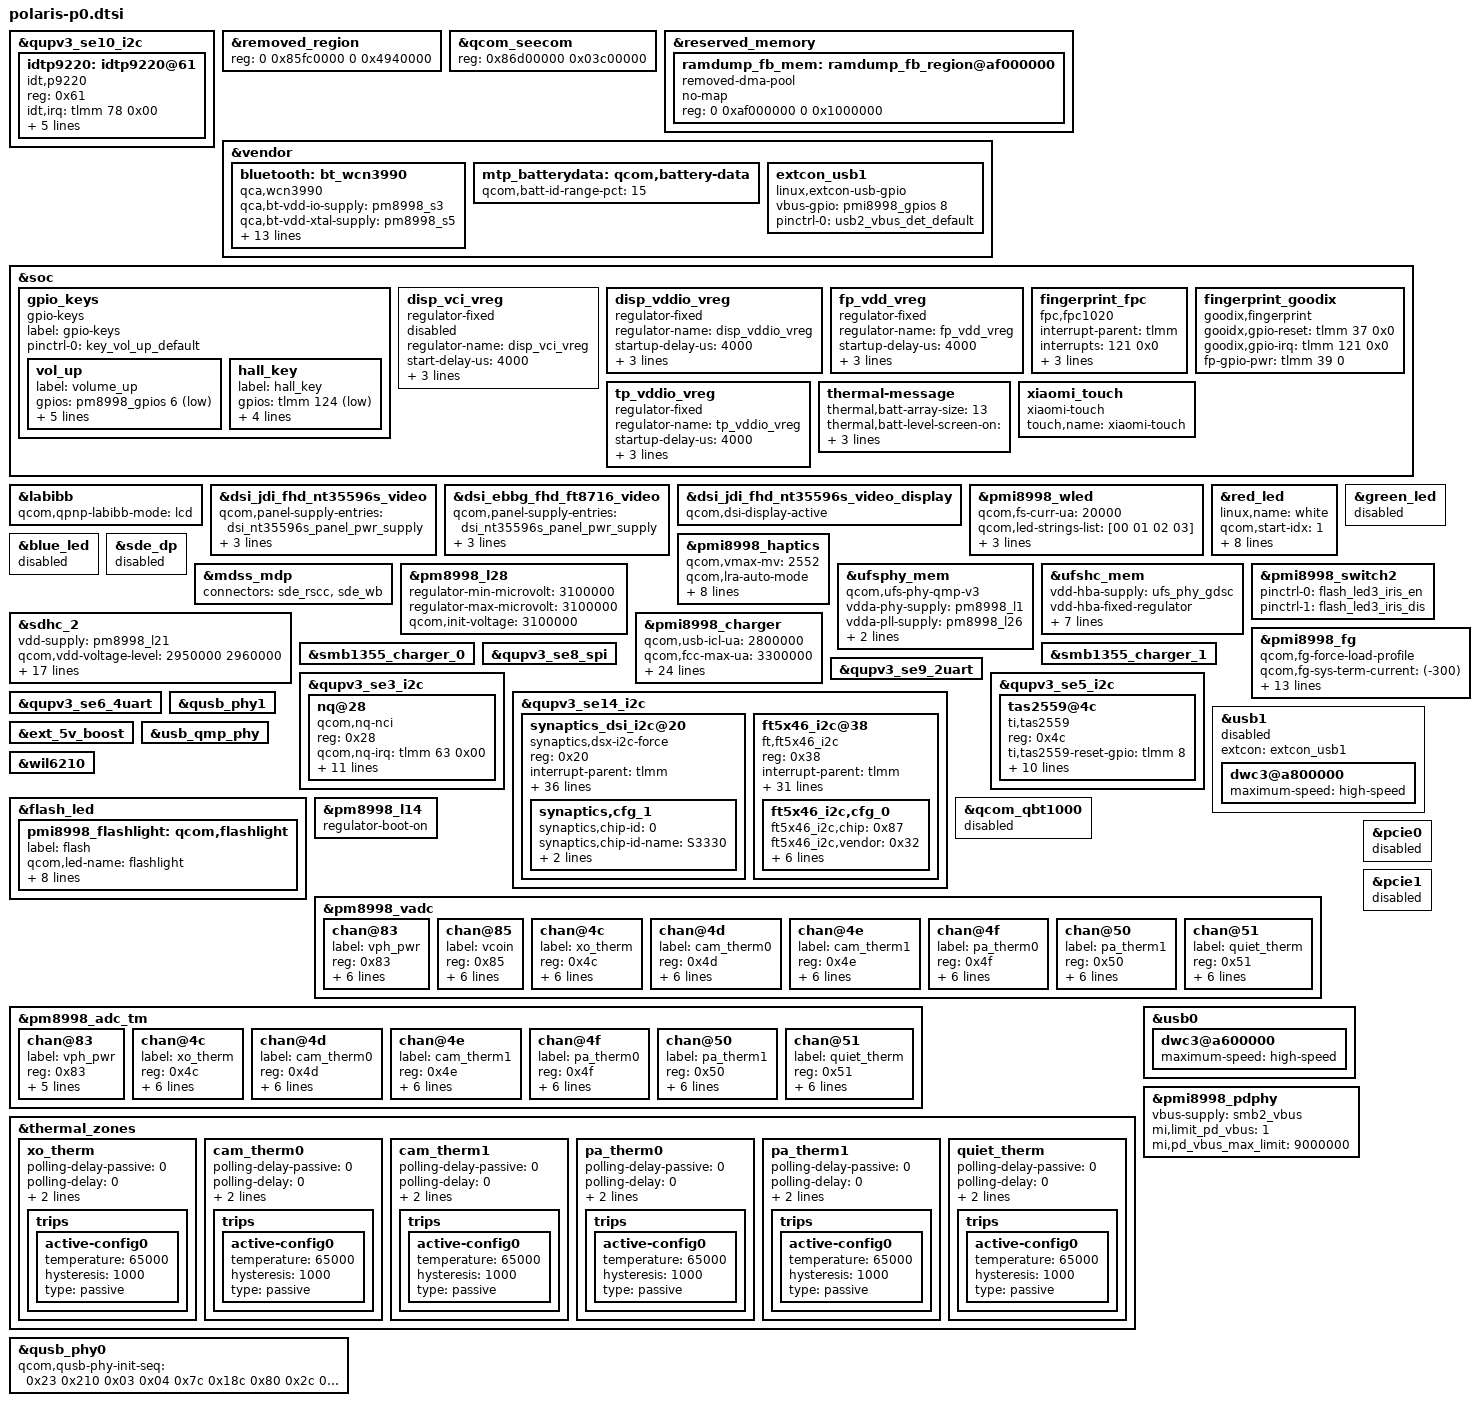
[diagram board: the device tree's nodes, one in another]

/* Copyright (c) 2016-2017, The Linux Foundation. All rights reserved.
 * Copyright (C) 2019 XiaoMi, Inc.
 *
 * This program is free software; you can redistribute it and/or modify
 * it under the terms of the GNU General Public License version 2 and
 * only version 2 as published by the Free Software Foundation.
 *
 * This program is distributed in the hope that it will be useful,
 * but WITHOUT ANY WARRANTY; without even the implied warranty of
 * MERCHANTABILITY or FITNESS FOR A PARTICULAR PURPOSE.  See the
 * GNU General Public License for more details.
 */

#include <dt-bindings/gpio/gpio.h>
#include "sdm845-pmic-overlay.dtsi"
#include "sdm845-pinctrl-overlay.dtsi"
#include "polaris-camera-sensor-mtp.dtsi"
#include "xiaomi-sde-display.dtsi"

&qupv3_se10_i2c {
#include "smb1355.dtsi"
};

&removed_region {
	reg = <0 0x85fc0000 0 0x4940000>;
};

&qcom_seecom {
	reg = <0x86d00000 0x03c00000>;
};

&reserved_memory {
		ramdump_fb_mem: ramdump_fb_region@af000000 {
			compatible = "removed-dma-pool";
			no-map;
			reg = <0 0xaf000000 0 0x1000000>;
		};
};

&vendor {
	bluetooth: bt_wcn3990 {
		compatible = "qca,wcn3990";
		qca,bt-vdd-io-supply = <&pm8998_s3>;
		qca,bt-vdd-xtal-supply = <&pm8998_s5>;
		qca,bt-vdd-core-supply = <&pm8998_l7>;
		qca,bt-vdd-pa-supply = <&pm8998_l17>;
		qca,bt-vdd-ldo-supply = <&pm8998_l25>;

		qca,bt-vdd-io-voltage-level = <1352000 1352000>;
		qca,bt-vdd-xtal-voltage-level = <2040000 2040000>;
		qca,bt-vdd-core-voltage-level = <1800000 1800000>;
		qca,bt-vdd-pa-voltage-level = <1304000 1304000>;
		qca,bt-vdd-ldo-voltage-level = <3312000 3312000>;

		qca,bt-vdd-io-current-level = <1>; /* LPM/PFM */
		qca,bt-vdd-xtal-current-level = <1>; /* LPM/PFM */
		qca,bt-vdd-core-current-level = <1>; /* LPM/PFM */
		qca,bt-vdd-pa-current-level = <1>; /* LPM/PFM */
		qca,bt-vdd-ldo-current-level = <1>; /* LPM/PFM */
	};
};

&soc {
	gpio_keys {
		compatible = "gpio-keys";
		label = "gpio-keys";

		pinctrl-names = "default";
		pinctrl-0 = <&key_vol_up_default>;

		vol_up {
			label = "volume_up";
			gpios = <&pm8998_gpios 6 GPIO_ACTIVE_LOW>;
			linux,input-type = <1>;
			linux,code = <115>;
			gpio-key,wakeup;
			debounce-interval = <15>;
			linux,can-disable;
		};
		hall_key {
			label = "hall_key";
			gpios = <&tlmm 124 GPIO_ACTIVE_LOW>;
			linux,input-type = <5>;
			linux,code = <0>;
			gpio-key,wakeup;
			debounce-interval = <15>;
		};
	};
	disp_vci_vreg: disp_vci_vreg {
		compatible = "regulator-fixed";
		regulator-name = "disp_vci_vreg";
		start-delay-us = <4000>;
		enable-active-high;
		regulator-boot-on;
		gpio = <&tlmm 35 0>;
	};

	disp_vddio_vreg: disp_vddio_vreg {
		compatible = "regulator-fixed";
		regulator-name = "disp_vddio_vreg";
		startup-delay-us = <4000>;
		enable-active-high;
		regulator-boot-on;
		gpio = <&tlmm 90 0>;
	 };

	fp_vdd_vreg: fp_vdd_vreg {
		compatible = "regulator-fixed";
		regulator-name = "fp_vdd_vreg";
		startup-delay-us = <4000>;
		enable-active-high;
		gpio = <&tlmm 39 0>;
		regulator-always-on;
	};

	fingerprint_fpc {
		status = "ok";
		compatible = "fpc,fpc1020";
		interrupt-parent = <&tlmm>;
		interrupts = <121 0x0>;
		fpc,gpio_irq    = <&tlmm 121 0x0>;
		/* fpc,enable-on-boot; */
		/* fpc,enable-wakeup;  */

		pinctrl-names = "fpc1020_reset_reset",
			"fpc1020_reset_active";

		pinctrl-0 = <&msm_gpio_37>;
		pinctrl-1 = <&msm_gpio_37_output_high>;
	};

	fingerprint_goodix {
		compatible = "goodix,fingerprint";
		gooidx,gpio-reset = <&tlmm 37 0x0>;
		goodix,gpio-irq = <&tlmm 121 0x0>;
		fp-gpio-pwr = <&tlmm 39 0>;
		status = "ok";
	};

    tp_vddio_vreg: tp_vddio_vreg {
	 compatible = "regulator-fixed";
	 regulator-name = "tp_vddio_vreg";
	 startup-delay-us = <4000>;
	 enable-active-high;
	 regulator-boot-on;
	 gpio = <&tlmm 23 0>;
     };

	thermal-message {
		thermal,batt-array-size = "13";
		thermal,batt-level-screen-on = "0 2 4 6 8 9 10 11 12 13 14 14 16";
		thermal,batt-level-screen-off = "0 1 1 1 3 4 5 5 5 7 9 14 16";
	};

	xiaomi_touch {
		compatible = "xiaomi-touch";
		status = "ok";
		touch,name = "xiaomi-touch";
	};

};

&labibb {
	status = "ok";
	qcom,qpnp-labibb-mode = "lcd";
};

&dsi_jdi_fhd_nt35596s_video {
	qcom,panel-supply-entries = <&dsi_nt35596s_panel_pwr_supply>;
	qcom,mdss-dsi-bl-pmic-control-type = "bl_ctrl_wled";
	qcom,platform-reset-gpio = <&tlmm 6 0>;
};

&dsi_ebbg_fhd_ft8716_video {
	qcom,panel-supply-entries = <&dsi_nt35596s_panel_pwr_supply>;
	qcom,mdss-dsi-bl-pmic-control-type = "bl_ctrl_wled";
	qcom,platform-reset-gpio = <&tlmm 6 0>;
};

&dsi_jdi_fhd_nt35596s_video_display {
	qcom,dsi-display-active;
};

&pmi8998_wled {
	status = "okay";
	qcom,fs-curr-ua = <20000>;
	qcom,led-strings-list = [00 01 02 03];
	qcom,ovp-mv = <19600>;
	qcom,en-cabc;
	qcom,switch-freq-khz = <600>;
};

&red_led {
	linux,name = "white";
	qcom,start-idx = <1>;
	qcom,idx-len = <18>;
	qcom,duty-pcts = [00 01 02 03 04 05 06 07 08
			08 07 06 05 04 03 02 01 00];
	qcom,lut-flags = <3>;
	qcom,pause-lo = <0>;
	qcom,pause-hi = <0>;
	qcom,ramp-step-ms = <142>;
	qcom,use-blink;
	status = "okay";
};

&green_led {
	status = "disabled";
};

&blue_led {
	status = "disabled";
};

&sde_dp {
	status = "disabled";
};

&disp_vci_vreg {
	status = "disabled";
};

&pmi8998_haptics {
	qcom,vmax-mv = <2552>;
	qcom,lra-auto-mode;
	qcom,wave-play-rate-us = <4878>;
	qcom,wave-shape = "sine";
	qcom,lra-high-z = "opt1";
	qcom,lra-auto-res-mode = "qwd";
	qcom,lra-res-cal-period = <4>;
	qcom,effect-max = <3>;
	qcom,effect-arry = [3e 3e be a0 00 00 00 00
	3e 3e 3e be be 00 00 00
	3e 3e 3e 3e be be a0 90];
	status = "okay";
};

&mdss_mdp {
	#cooling-cells = <2>;
	connectors = <&sde_rscc &sde_wb>;
};

&pm8998_l28{
	regulator-min-microvolt = <3100000>;
	regulator-max-microvolt = <3100000>;
	qcom,init-voltage = <3100000>;
};

&ufsphy_mem {
	compatible = "qcom,ufs-phy-qmp-v3";

	vdda-phy-supply = <&pm8998_l1>; /* 0.88v */
	vdda-pll-supply = <&pm8998_l26>; /* 1.2v */
	vdda-phy-max-microamp = <62900>;
	vdda-pll-max-microamp = <18300>;

	status = "ok";
};

&ufshc_mem {
	vdd-hba-supply = <&ufs_phy_gdsc>;
	vdd-hba-fixed-regulator;
	vcc-supply = <&pm8998_l20>;
	vcc-voltage-level = <2950000 2960000>;
	vccq2-supply = <&pm8998_s4>;
	vcc-max-microamp = <600000>;
	vccq2-max-microamp = <600000>;

	qcom,vddp-ref-clk-supply = <&pm8998_l2>;
	qcom,vddp-ref-clk-max-microamp = <100>;

	status = "ok";
};

&sdhc_2 {
	vdd-supply = <&pm8998_l21>;
	qcom,vdd-voltage-level = <2950000 2960000>;
	qcom,vdd-current-level = <200 800000>;

	vdd-io-supply = <&pm8998_l13>;
	qcom,vdd-io-voltage-level = <1808000 2960000>;
	qcom,vdd-io-current-level = <200 22000>;

	pinctrl-names = "active", "sleep", "ds_400KHz",
			"ds_50MHz", "ds_100MHz", "ds_200MHz";
	pinctrl-0 = <&sdc2_clk_on  &sdc2_cmd_on &sdc2_data_on &storage_cd>;
	pinctrl-1 = <&sdc2_clk_off &sdc2_cmd_off &sdc2_data_off &storage_cd>;
	pinctrl-2 = <&sdc2_clk_ds_400KHz
			&sdc2_cmd_ds_400KHz &sdc2_data_ds_400KHz>;
	pinctrl-3 = <&sdc2_clk_ds_50MHz
			&sdc2_cmd_ds_50MHz &sdc2_data_ds_50MHz>;
	pinctrl-4 = <&sdc2_clk_ds_100MHz
			&sdc2_cmd_ds_100MHz &sdc2_data_ds_100MHz>;
	pinctrl-5 = <&sdc2_clk_ds_200MHz
			&sdc2_cmd_ds_200MHz &sdc2_data_ds_200MHz>;

	cd-gpios = <&tlmm 126 GPIO_ACTIVE_LOW>;

	status = "ok";
};

&pmi8998_switch2 {
	pinctrl-names = "led_enable", "led_disable";
	pinctrl-0 = <&flash_led3_iris_en>;
	pinctrl-1 = <&flash_led3_iris_dis>;
};

&vendor{
	mtp_batterydata: qcom,battery-data {
		qcom,batt-id-range-pct = <15>;
		#include "batterydata-d5-atl-3400mAh.dtsi"
		#include "batterydata-d5-cos-3400mAh.dtsi"
		#include "batterydata-itech-3020mAh.dtsi"
	};

	extcon_usb1: extcon_usb1 {
		compatible = "linux,extcon-usb-gpio";
		vbus-gpio = <&pmi8998_gpios 8 GPIO_ACTIVE_HIGH>;

		pinctrl-names = "default";
		pinctrl-0 = <&usb2_vbus_det_default>;
	};
};
&pmi8998_charger {
	qcom,usb-icl-ua = <2800000>;
	qcom,fcc-max-ua = <3300000>;
	qcom,dc-icl-ua = <950000>;
	qcom,fcc-low-temp-delta = <2970000>;
	qcom,fcc-hot-temp-delta = <1650000>;
	qcom,fcc-cool-temp-delta = <2310000>;
	qcom,auto-recharge-soc;
	 qcom,sw-jeita-enable;
	qcom,dynamic-fv-enable;
	qcom,wireless-flag;
	qcom,wireless-support;
	qcom,thermal-mitigation
				= <1800000 1600000 1400000 1200000 1000000 1000000 1000000>;
	qcom,thermal-mitigation-dc
				= <800000 550000 450000 325000>;
	qcom,thermal-mitigation-dcp
				= <1800000 1800000 1800000 1800000 1800000 1800000 1800000
				   1800000 1800000 1800000 1800000 1800000 1600000 1400000
				   1200000 1000000>;
	qcom,thermal-mitigation-qc3
				= <2800000 2725000 2575000 2425000 2275000 2125000 2000000
				   1800000 1650000 1500000 1360000 1200000 1060000 900000
				   752500 525000>;
	qcom,thermal-mitigation-qc2
				= <1625000 1625000 1625000 1625000 1625000 1525000 1425000
				   1325000 1225000 1125000 10255000 925000 825000 725000
				   625000 525000>;
	qcom,thermal-mitigation-pd-base
				= <3000000 2800000 2600000 2400000 2200000 2000000 1800000
				   1600000 1600000 1400000 1200000 1100000 1000000 900000
				   752500 525000>;

	io-channels = <&pmi8998_rradc 8>,
		<&pmi8998_rradc 10>,
		<&pmi8998_rradc 3>,
		<&pmi8998_rradc 4>,
		<&pmi8998_rradc 5>;
	io-channel-names = "charger_temp",
		"charger_temp_max",
		"usbin_i",
		"usbin_v",
		"dcin_i";
};

&pmi8998_fg {
	qcom,fg-force-load-profile;
	qcom,fg-sys-term-current = <(-300)>;
	qcom,fg-chg-term-current = <200>;
	qcom,fg-auto-recharge-soc;
	qcom,fg-recharge-soc-thr = <99>;
	qcom,fg-cutoff-voltage = <3400>;
	qcom,fg-cutoff-current = <200>;
	qcom,fg-empty-voltage = <3100>;
	qcom,fg-jeita-hyst-temp = <2>;
	qcom,fg-jeita-thresholds = <0 15 45 60>;
	qcom,fg-esr-clamp-mohms = <60>;
	qcom,fg-batt-temp-delta = <6>;
	qcom,battery-data = <&mtp_batterydata>;
	qcom,slope-limit-temp-threshold = <100>;
	qcom,slope-limit-coeffs = <10 11 12 13>;
};

&smb1355_charger_0 {
	status = "ok";
};

&smb1355_charger_1 {
	status = "ok";
};

&qupv3_se9_2uart {
	status = "ok";
};

&qupv3_se8_spi {
	status = "ok";
};

&qupv3_se3_i2c {
	status = "ok";
	nq@28 {
		compatible = "qcom,nq-nci";
		reg = <0x28>;
		qcom,nq-irq = <&tlmm 63 0x00>;
		qcom,nq-ven = <&tlmm 12 0x00>;
		qcom,nq-firm = <&tlmm 88 0x00>;
		qcom,nq-clkreq = <&pm8998_gpios 21 0x00>;
		qcom,nq-esepwr = <&tlmm 116 0x00>;
		interrupt-parent = <&tlmm>;
		qcom,clk-src = "BBCLK3";
		interrupts = <63 0>;
		interrupt-names = "nfc_irq";
		pinctrl-names = "nfc_active", "nfc_suspend";
		 pinctrl-0 = <&nfc_int_active
		              &nfc_enable_active
		              &nfc_clk_default>;
		pinctrl-1 = <&nfc_int_suspend &nfc_enable_suspend>;
		clocks = <&clock_rpmh RPMH_LN_BB_CLK3>;
		clock-names = "ref_clk";
	};
};

&qupv3_se5_i2c {
	status = "ok";
	/*smart PA*/
	tas2559@4c{
		compatible = "ti,tas2559";
		reg = <0x4c>;
		ti,tas2559-reset-gpio = <&tlmm 8 0>;
		ti,tas2560-reset-gpio = <&tlmm 25 0>;
		ti,tas2559-irq-gpio = <&tlmm 24 0>;
		ti,tas2560-irq-gpio = <&tlmm 30 0>;
		ti,tas2559-addr = <0x4c>;
		ti,tas2560-addr = <0x4d>;
		ti,tas2559-channel = <0>; /* 0, left; 1, right */
		ti,tas2560-channel = <1>; /* 0, left; 1, right */
		ti,ycrc-enable = <1>;           /* 0, disable; non-zero, enable */
		ti,echo-ref = <0>;              /* 0, left channel; 1, right channel; 2, both */
		ti,bit-rate = <16>;             /* 16, 20, 24, 32 */
		status = "ok";
	};

};

&qupv3_se10_i2c {
	status = "ok";
	idtp9220: idtp9220@61 {
		compatible = "idt,p9220";
		reg = <0x61>;
		idt,irq = <&tlmm 78 0x00>;
		idt,enable = <&tlmm 36 0x00>;
		interrupt-parent = <&tlmm>;
		interrupts = <78 0>;
		interrupt-names = "idt_irq";
		pinctrl-names = "idt_active", "idt_suspend";
		pinctrl-0 = <&idt_int_active &idt_enable_active>;
		pinctrl-1 = <&idt_int_suspend &idt_enable_suspend>;
	};
};

&qupv3_se14_i2c {
	status = "ok";
	synaptics_dsi_i2c@20 {
		compatible = "synaptics,dsx-i2c-force";
		reg = <0x20>;
		interrupt-parent = <&tlmm>;
		interrupts = <125 0x2008>;
		vdd-supply = <&tp_vddio_vreg>;
		lab-supply = <&lab_regulator>;
		ibb-supply = <&ibb_regulator>;
		disp-supply = <&pm8998_l14>;
		avdd-supply = <&pm8998_l28>;
		synaptics,pwr-reg-name = "vdd";
		synaptics,lab-reg-name = "lab";
		synaptics,ibb-reg-name = "ibb";
		synaptics,disp-reg-name = "disp";
		synaptics,bus-reg-name = "avdd";
		synaptics,disp-power-hold;
		synaptics,ub-i2c-addr = <0x2c>;
		pinctrl-names = "pmx_ts_active", "pmx_ts_suspend";
		pinctrl-0 = <&ts_active>;
		pinctrl-1 = <&ts_int_suspend &ts_reset_suspend>;
		/*synaptics,palm-rx-channel = <10>;*/
		/*synaptics,palm-rx-area = <400>;*/
		/*synaptics,palm-tx-disable = <4>;*/
		synaptics,drm-dsi-reset = <&tlmm 6 0>;
		synaptics,reset-gpio = <&tlmm 99 0x00>;
		synaptics,irq-gpio = <&tlmm  125 0x2008>;
		synaptics,reset-gpio-name = "dsx_reset";
		synaptics,irq-gpio-name = "dsx_irq";
		synaptics,irq-on-state = <0>;
		synaptics,irq-flags = <0x2008>; /* IRQF_ONESHOT | IRQF_TRIGGER_LOW */
		synaptics,power-delay-ms = <5>;
		synaptics,reset-delay-ms = <200>;
		synaptics,reset-active-ms = <5>;
		synaptics,power-on-state = <1>;
		synaptics,reset-on-state = <0>;
		synaptics,drm-reset-state = <1>;
		synaptics,panel-is-incell;
		synaptics,short-jdi-25 = "000: 0xff\n001: 0xff\n002: 0xff\n003: 0xf7\n004: 0x03\n005: 0x00\n006: 0x00";
		synaptics,short-jdi-26 = "000: 0x03\n001: 0x00\n002: 0x00\n003: 0x00\n004: 0x03\n005: 0x00\n006: 0x00";
		/*clock-names = "iface_clk", "core_clk";
		clocks = <&clock_gcc clk_gcc_blsp1_ahb_clk>,
			 <&clock_gcc clk_gcc_blsp1_qup5_i2c_apps_clk>;
			 */
		synaptics,guest-serialization-as-lockdown;
		synaptics,tp-id-byte = /bits/ 8 <0>;
		synaptics,config-array-size = <1>;
		synaptics,cfg_1 {
			synaptics,chip-id = <0>;
			synaptics,chip-id-name = "S3330";
			synaptics,tp-id = /bits/ 8 <0x31>;
			synaptics,fw-name = "synaptics_jdi_3330_d5x.fw";
		};
	};
	ft5x46_i2c@38 {
		compatible = "ft,ft5x46_i2c";
		reg = <0x38>;
		interrupt-parent = <&tlmm>;
		interrupts = <125 0x2008>;
		vddio-supply = <&tp_vddio_vreg>;
		vdd-supply = <&pm8998_l14>;
		lab-supply = <&lab_regulator>;
		ibb-supply = <&ibb_regulator>;
		/* pins used by touchscreen */
		pinctrl-names = "pmx_ts_active","pmx_ts_suspend";
		pinctrl-0 = <&ts_active>;
		pinctrl-1 = <&ts_int_suspend &ts_reset_suspend>;
		ft5x46_i2c,i2c-pull-up;
		ft5x46_i2c,irqflags = <0x2008>;
		ft5x46_i2c,x-max = <1080>;
		ft5x46_i2c,y-max = <2160>;
		ft5x46_i2c,z-max = <255>;
		ft5x46_i2c,w-max = <200>;
		ft5x46_i2c,reset-gpio = <&tlmm 99 0x00>;
		ft5x46_i2c,irq-gpio = <&tlmm 125 0x2008>;
		ft5x46_i2c,skip-reset-in-resume;
		ft5x46_i2c,landing-jiffies = <1000>;
		ft5x46_i2c,landing-threshold = <16>;
		ft5x46_i2c,staying-threshold = <8>;
		ft5x46_i2c,raw-min = <7000>;
		ft5x46_i2c,raw-max = <10000>;
		ft5x46_i2c,open-min = <60>;
		ft5x46_i2c,open-max = <200>;
		ft5x46_i2c,short-min = <200>;
		ft5x46_i2c,short-max = <100000000>;
		ft5x46_i2c,fw-delay-55-ms = <2>;
		ft5x46_i2c,fw-delay-aa-ms = <2>;
		ft5x46_i2c,fw-upgrade-id1 = <0xE7>;
		ft5x46_i2c,fw-upgrade-id2 = <0xA6>;
		ft5x46_i2c,fw-delay-readid-ms = <20>;
		ft5x46_i2c,firmware-array-size = <1>;
		ft5x46_i2c,cfg_0 {
			ft5x46_i2c,chip = <0x87>;
			ft5x46_i2c,vendor = <0x32>;
			ft5x46_i2c,tp-vendor = <0x31>;
			ft5x46_i2c,lcd-vendor = <0x37>;
			ft5x46_i2c,fw-name = "ft8716_ebbg_incell_ebbg_d5x.fw";
			ft5x46_i2c,tx-num = <24>;
			ft5x46_i2c,rx-num = <13>;
		};
	};

};

&qupv3_se6_4uart {
	status = "ok";
};

&usb1 {
	status = "disabled";
	extcon = <&extcon_usb1>;
};

&qusb_phy1 {
	status = "okay";
};

&ext_5v_boost {
	status = "ok";
};

&usb_qmp_phy {
	status = "okay";
};

&wil6210 {
	status = "ok";
};

&flash_led {
	pmi8998_flashlight: qcom,flashlight {
		label = "flash";
		qcom,led-name = "flashlight";
		qcom,max-current = <750>;
		qcom,default-led-trigger = "flashlight_trigger";
		qcom,id = <3>;
		qcom,current-ma = <500>;
		qcom,duration-ms = <1280>;
		qcom,ires-ua = <12500>;
		qcom,hdrm-voltage-mv = <325>;
		qcom,hdrm-vol-hi-lo-win-mv = <100>;
	};
};

&pm8998_l14 {
	regulator-boot-on;
};

&qcom_qbt1000 {
	status = "disabled";
};

&pm8998_vadc {
	chan@83 {
		label = "vph_pwr";
		reg = <0x83>;
		qcom,decimation = <2>;
		qcom,pre-div-channel-scaling = <1>;
		qcom,calibration-type = "absolute";
		qcom,scale-function = <0>;
		qcom,hw-settle-time = <0>;
		qcom,fast-avg-setup = <0>;
	};

	chan@85 {
		label = "vcoin";
		reg = <0x85>;
		qcom,decimation = <2>;
		qcom,pre-div-channel-scaling = <1>;
		qcom,calibration-type = "absolute";
		qcom,scale-function = <0>;
		qcom,hw-settle-time = <0>;
		qcom,fast-avg-setup = <0>;
	};

	chan@4c {
		label = "xo_therm";
		reg = <0x4c>;
		qcom,decimation = <2>;
		qcom,pre-div-channel-scaling = <0>;
		qcom,calibration-type = "ratiometric";
		qcom,scale-function = <4>;
		qcom,hw-settle-time = <2>;
		qcom,fast-avg-setup = <0>;
	};

	chan@4d {
		label = "cam_therm0";
		reg = <0x4d>;
		qcom,decimation = <2>;
		qcom,pre-div-channel-scaling = <0>;
		qcom,calibration-type = "ratiometric";
		qcom,scale-function = <2>;
		qcom,hw-settle-time = <2>;
		qcom,fast-avg-setup = <0>;
	};

	chan@4e {
		label = "cam_therm1";
		reg = <0x4e>;
		qcom,decimation = <2>;
		qcom,pre-div-channel-scaling = <0>;
		qcom,calibration-type = "ratiometric";
		qcom,scale-function = <2>;
		qcom,hw-settle-time = <2>;
		qcom,fast-avg-setup = <0>;
	};

	chan@4f {
		label = "pa_therm0";
		reg = <0x4f>;
		qcom,decimation = <2>;
		qcom,pre-div-channel-scaling = <0>;
		qcom,calibration-type = "ratiometric";
		qcom,scale-function = <2>;
		qcom,hw-settle-time = <2>;
		qcom,fast-avg-setup = <0>;
	};

	chan@50 {
		label = "pa_therm1";
		reg = <0x50>;
		qcom,decimation = <2>;
		qcom,pre-div-channel-scaling = <0>;
		qcom,calibration-type = "ratiometric";
		qcom,scale-function = <2>;
		qcom,hw-settle-time = <2>;
		qcom,fast-avg-setup = <0>;
	};

	chan@51 {
		label = "quiet_therm";
		reg = <0x51>;
		qcom,decimation = <2>;
		qcom,pre-div-channel-scaling = <0>;
		qcom,calibration-type = "ratiometric";
		qcom,scale-function = <2>;
		qcom,hw-settle-time = <2>;
		qcom,fast-avg-setup = <0>;
	};
};

&pm8998_adc_tm {
	chan@83 {
		label = "vph_pwr";
		reg = <0x83>;
		qcom,pre-div-channel-scaling = <1>;
		qcom,calibration-type = "absolute";
		qcom,scale-function = <0>;
		qcom,hw-settle-time = <0>;
		qcom,btm-channel-number = <0x60>;
	};

	chan@4c {
		label = "xo_therm";
		reg = <0x4c>;
		qcom,pre-div-channel-scaling = <0>;
		qcom,calibration-type = "ratiometric";
		qcom,scale-function = <4>;
		qcom,hw-settle-time = <2>;
		qcom,btm-channel-number = <0x68>;
		qcom,thermal-node;
	};

	chan@4d {
		label = "cam_therm0";
		reg = <0x4d>;
		qcom,pre-div-channel-scaling = <0>;
		qcom,calibration-type = "ratiometric";
		qcom,scale-function = <2>;
		qcom,hw-settle-time = <2>;
		qcom,btm-channel-number = <0x88>;
		qcom,thermal-node;
	};

	chan@4e {
		label = "cam_therm1";
		reg = <0x4e>;
		qcom,pre-div-channel-scaling = <0>;
		qcom,calibration-type = "ratiometric";
		qcom,scale-function = <2>;
		qcom,hw-settle-time = <2>;
		qcom,btm-channel-number = <0x70>;
		qcom,thermal-node;
	};

	chan@4f {
		label = "pa_therm0";
		reg = <0x4f>;
		qcom,pre-div-channel-scaling = <0>;
		qcom,calibration-type = "ratiometric";
		qcom,scale-function = <2>;
		qcom,hw-settle-time = <2>;
		qcom,btm-channel-number = <0x78>;
		qcom,thermal-node;
	};

	chan@50 {
		label = "pa_therm1";
		reg = <0x50>;
		qcom,pre-div-channel-scaling = <0>;
		qcom,calibration-type = "ratiometric";
		qcom,scale-function = <2>;
		qcom,hw-settle-time = <2>;
		qcom,btm-channel-number = <0x90>;
		qcom,thermal-node;
	};

	chan@51 {
		label = "quiet_therm";
		reg = <0x51>;
		qcom,pre-div-channel-scaling = <0>;
		qcom,calibration-type = "ratiometric";
		qcom,scale-function = <2>;
		qcom,hw-settle-time = <2>;
		qcom,btm-channel-number = <0x80>;
		qcom,thermal-node;
	};
};

&thermal_zones {
	xo_therm {
		polling-delay-passive = <0>;
		polling-delay = <0>;
		thermal-sensors = <&pm8998_adc_tm 0x4c>;
		thermal-governor = "user_space";

		trips {
			active-config0 {
				temperature = <65000>;
				hysteresis = <1000>;
				type = "passive";
			};
		};
	};

	cam_therm0 {
		polling-delay-passive = <0>;
		polling-delay = <0>;
		thermal-sensors = <&pm8998_adc_tm 0x4d>;
		thermal-governor = "user_space";

		trips {
			active-config0 {
					temperature = <65000>;
					hysteresis = <1000>;
					type = "passive";
			};
		};
	};

	cam_therm1 {
		polling-delay-passive = <0>;
		polling-delay = <0>;
		thermal-sensors = <&pm8998_adc_tm 0x4e>;
		thermal-governor = "user_space";

		trips {
			active-config0 {
					temperature = <65000>;
					hysteresis = <1000>;
					type = "passive";
			};
		};
	};

	pa_therm0 {
		polling-delay-passive = <0>;
		polling-delay = <0>;
		thermal-sensors = <&pm8998_adc_tm 0x4f>;
		thermal-governor = "user_space";

		trips {
			active-config0 {
					temperature = <65000>;
					hysteresis = <1000>;
					type = "passive";
			};
		};
	};

	pa_therm1 {
		polling-delay-passive = <0>;
		polling-delay = <0>;
		thermal-sensors = <&pm8998_adc_tm 0x50>;
		thermal-governor = "user_space";

		trips {
			active-config0 {
					temperature = <65000>;
					hysteresis = <1000>;
					type = "passive";
			};
		};
	};

	quiet_therm {
		polling-delay-passive = <0>;
		polling-delay = <0>;
		thermal-sensors = <&pm8998_adc_tm 0x51>;
		thermal-governor = "user_space";

		trips {
			active-config0 {
				temperature = <65000>;
				hysteresis = <1000>;
				type = "passive";
			};
		};
	};
};

&usb0 {
	dwc3@a600000 {
		maximum-speed = "high-speed";
	};
};

&usb1 {
	dwc3@a800000 {
		maximum-speed = "high-speed";
	};
};

&pcie0 {
	status = "disabled";
};

&pcie1 {
	status = "disabled";
};

&qusb_phy0 {
		qcom,qusb-phy-init-seq =
			/* <value reg_offset> */
			   <0x23 0x210 /* PWR_CTRL1 */
			    0x03 0x04  /* PLL_ANALOG_CONTROLS_TWO */
			    0x7c 0x18c /* PLL_CLOCK_INVERTERS */
			    0x80 0x2c  /* PLL_CMODE */
			    0x0a 0x184 /* PLL_LOCK_DELAY */
			    0x19 0xb4  /* PLL_DIGITAL_TIMERS_TWO */
			    0x40 0x194 /* PLL_BIAS_CONTROL_1 */
			    0x12 0x198 /* PLL_BIAS_CONTROL_2 */
			    0x21 0x214 /* PWR_CTRL2 */
			    0x08 0x220 /* IMP_CTRL1 */
			    0x58 0x224 /* IMP_CTRL2 */
			    0x07 0x240 /* TUNE1 */
			    0x2b 0x244 /* TUNE2 */
			    0xca 0x248 /* TUNE3 */
			    0x04 0x24c /* TUNE4 */
			    0x03 0x250 /* TUNE5 */
			    0x00 0x23c /* CHG_CTRL2 */
			    0x22 0x210>; /* PWR_CTRL1 */
};

&pmi8998_pdphy {
			vbus-supply = <&smb2_vbus>;
			/*mi,limit_pd_vbus 1:enable 0:disable*/
			mi,limit_pd_vbus = <1>;
			mi,pd_vbus_max_limit = <9000000>;
};

